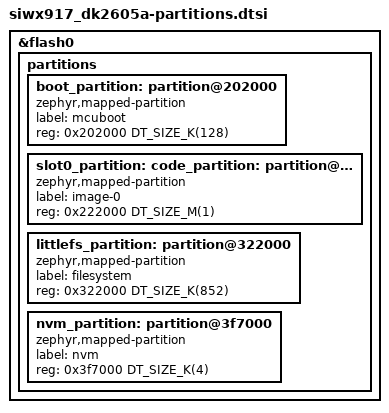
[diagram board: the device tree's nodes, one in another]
/* Partition layout for siwx917_dk2605a: the flash memory map shared by the
 * bootloader and every application image. Generated by
 * tools/partition_layout.py; do not edit by hand -- re-run
 * `python3 tools/partition_layout.py --fix siwx917_dk2605a` after changing
 * the upstream board geometry or tools/boards.toml.
 *
 * Board-specific overlay glue (delete-nodes, device enablement,
 * aliases/chosen) lives in dts/silabs/siwx917_dk2605a.dtsi, which includes
 * this file.
 */

/delete-node/ &code_partition;

&flash0 {
	partitions {
		boot_partition: partition@202000 {
			compatible = "zephyr,mapped-partition";
			label = "mcuboot";
			reg = <0x202000 DT_SIZE_K(128)>;
		};

		slot0_partition: code_partition: partition@222000 {
			compatible = "zephyr,mapped-partition";
			label = "image-0";
			reg = <0x222000 DT_SIZE_M(1)>;
		};

		littlefs_partition: partition@322000 {
			compatible = "zephyr,mapped-partition";
			label = "filesystem";
			reg = <0x322000 DT_SIZE_K(852)>;
		};

		nvm_partition: partition@3f7000 {
			compatible = "zephyr,mapped-partition";
			label = "nvm";
			reg = <0x3f7000 DT_SIZE_K(4)>;
		};

		/* Single-app layout: the rest of this flash is owned by the
		 * ROM loader / network processor (the partitions below), leaving
		 * no room for a second slot next to the filesystem. Updates are
		 * written straight into slot0 by the bootloader (UF2 / serial
		 * recovery) instead of a mcuboot slot1 swap.
		 *
		 * Inherited from the upstream dts and kept as-is
		 * (not re-emitted here):
		 *   mbr_nwp (mbr_nwp_partition): 0x0 + DT_SIZE_K(68)
		 *   code_nwp (code_nwp_partition): 0x11000 + DT_SIZE_K(1916)
		 *   mbr (mbr_partition): 0x1f0000 + DT_SIZE_K(68)
		 *   hdr (hdr_partition): 0x201000 + DT_SIZE_K(4)
		 *   storage (storage_partition): 0x3f8000 + DT_SIZE_K(32)
		 *   ota_swap (ota_swap_partition): 0x400000 + DT_SIZE_K(3900)
		 *   storage_nwp (storage_nwp_partition): 0x7cf000 + DT_SIZE_K(160)
		 *   storage_shared (storage_shared_partition): 0x7f7000 + DT_SIZE_K(20)
		 *   backup_bootloader (backup_bootloader_partition): 0x7fc000 + DT_SIZE_K(16)
		 */
	};
};
